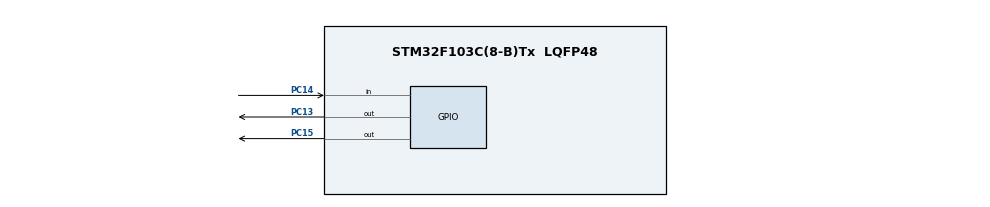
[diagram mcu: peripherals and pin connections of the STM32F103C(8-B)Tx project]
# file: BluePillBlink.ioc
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Mcu.Family=STM32F1
Mcu.Name=STM32F103C(8-B)Tx
Mcu.Package=LQFP48
NVIC.PriorityGroup=NVIC_PRIORITYGROUP_4
PC13-TAMPER-RTC.GPIO_ModeDefaultOutputPP=GPIO_MODE_OUTPUT_PP
PC13-TAMPER-RTC.GPIO_PuPd=GPIO_PULLDOWN
PC13-TAMPER-RTC.GPIO_Speed=GPIO_SPEED_FREQ_HIGH
PC13-TAMPER-RTC.Signal=GPIO_Output
PC14-OSC32_IN.GPIO_PuPd=GPIO_PULLDOWN
PC14-OSC32_IN.Signal=GPIO_Input
PC15-OSC32_OUT.GPIO_PuPd=GPIO_PULLDOWN
PC15-OSC32_OUT.GPIO_Speed=GPIO_SPEED_FREQ_HIGH
PC15-OSC32_OUT.Signal=GPIO_Output
ProjectManager.HeapSize=0x200
ProjectManager.StackSize=0x400
ProjectManager.TargetToolchain=STM32CubeIDE
RCC.APB1Freq_Value=8000000
RCC.APB2Freq_Value=8000000
VP_SYS_VS_ND.Mode=No_Debug
board=custom

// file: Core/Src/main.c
/* USER CODE BEGIN Header */
/**
  ******************************************************************************
  * @file           : main.c
  * @brief          : Main program body
  * @author			: Liyanage Kalana Perera
  *
  ******************************************************************************
  * @attention
  *
  * <h2><center>&copy; Copyright (c) 2023 STMicroelectronics.
  * All rights reserved.</center></h2>
  *
  * This software component is licensed by ST under BSD 3-Clause license,
  * the "License"; You may not use this file except in compliance with the
  * License. You may obtain a copy of the License at:
  *                        opensource.org/licenses/BSD-3-Clause
  *
  *
  * NOTE :
  * --> CONNECTIONS FROM ST-LINK TO STM32 BLUE PILL:
  * 	   SWIO  --> SWDIO
  * 	   SWCLK --> SWCLK
  *
  * --> THERE IS NO "RUN" BUTTON IN THIS VERSION OF IDE. SO TO PROGRAM WE CAN USE "RELESE" BY CLICK ON THE "HAMMER ICON".
  *	--> SET THE BOOT JUMPERS TO
  *		   BOOT0 --> 1
  *		   BOOT1 --> 0
  * --> THE LOGIC IS INVERT FOR THE BUILT IN LED IN C13.
  ******************************************************************************
  */
/* USER CODE END Header */

#include "main.h"

void SystemClock_Config(void);
static void MX_GPIO_Init(void);

/* USER CODE BEGIN 0 */
int PB_STAT,PB_FLAG;
/* USER CODE END 0 */

int main(void)
{

  /* MCU Configuration--------------------------------------------------------*/

  /* Reset of all peripherals, Initializes the Flash interface and the Systick. */
  HAL_Init();

  /* Configure the system clock */
  SystemClock_Config();

  /* Initialize all configured peripherals */
  MX_GPIO_Init();

  /* Infinite loop */
  /* USER CODE BEGIN WHILE */
  while (1)
  {
	  // READ FROM PIN C14 AND STORE IT IN THE "PB_STAT".
	  // CUSTOM DEBOUNCING PART ADDED.
	  PB_STAT = HAL_GPIO_ReadPin(GPIOC, GPIO_PIN_14);
	  // REMEMBER FOR SOME WEIRED RESEON, 1=0 AND 0=1,
	  // FORGET ABOUT THE COMMENT ABOVE. IT'S ONLY VALID FOR THE BUILT IN LED IN C13.
	  // OTHERTHAN THIS, THE LOGIC WORKS FINE.
	  if(PB_STAT == 1 && PB_FLAG == 0)
	   {
		 HAL_Delay(10);
		 PB_FLAG = 1;
	   }
	  if(PB_STAT == 0 && PB_FLAG == 1)
	  	   {
	  		for(int i=0;i<10;i++)
	  		 {
	  		  HAL_GPIO_TogglePin(GPIOC, GPIO_PIN_13);
	  		  HAL_GPIO_TogglePin(GPIOC, GPIO_PIN_15);
	  		  HAL_Delay(50);
	  		 }
	  		PB_FLAG = 0;
	   }else
	   {
		 HAL_GPIO_WritePin(GPIOC, GPIO_PIN_13, GPIO_PIN_RESET);
		 HAL_GPIO_WritePin(GPIOC, GPIO_PIN_15, GPIO_PIN_RESET);
	   }
    /* USER CODE END WHILE */

  }
}

void SystemClock_Config(void)
{
  RCC_OscInitTypeDef RCC_OscInitStruct = {0};
  RCC_ClkInitTypeDef RCC_ClkInitStruct = {0};

  /** Initializes the CPU, AHB and APB busses clocks
  */
  RCC_OscInitStruct.OscillatorType = RCC_OSCILLATORTYPE_HSI;
  RCC_OscInitStruct.HSIState = RCC_HSI_ON;
  RCC_OscInitStruct.HSICalibrationValue = RCC_HSICALIBRATION_DEFAULT;
  RCC_OscInitStruct.PLL.PLLState = RCC_PLL_NONE;
  if (HAL_RCC_OscConfig(&RCC_OscInitStruct) != HAL_OK)
  {
    Error_Handler();
  }
  /** Initializes the CPU, AHB and APB busses clocks
  */
  RCC_ClkInitStruct.ClockType = RCC_CLOCKTYPE_HCLK|RCC_CLOCKTYPE_SYSCLK
                              |RCC_CLOCKTYPE_PCLK1|RCC_CLOCKTYPE_PCLK2;
  RCC_ClkInitStruct.SYSCLKSource = RCC_SYSCLKSOURCE_HSI;
  RCC_ClkInitStruct.AHBCLKDivider = RCC_SYSCLK_DIV1;
  RCC_ClkInitStruct.APB1CLKDivider = RCC_HCLK_DIV1;
  RCC_ClkInitStruct.APB2CLKDivider = RCC_HCLK_DIV1;

  if (HAL_RCC_ClockConfig(&RCC_ClkInitStruct, FLASH_LATENCY_0) != HAL_OK)
  {
    Error_Handler();
  }
}

static void MX_GPIO_Init(void)
{
  GPIO_InitTypeDef GPIO_InitStruct = {0};

  /* GPIO Ports Clock Enable */
  __HAL_RCC_GPIOC_CLK_ENABLE();

  /*Configure GPIO pin Output Level */
  HAL_GPIO_WritePin(GPIOC, GPIO_PIN_13|GPIO_PIN_15, GPIO_PIN_RESET);

  /*Configure GPIO pins : PC13 PC15 */
  GPIO_InitStruct.Pin = GPIO_PIN_13|GPIO_PIN_15;
  GPIO_InitStruct.Mode = GPIO_MODE_OUTPUT_PP;
  GPIO_InitStruct.Pull = GPIO_PULLDOWN;
  GPIO_InitStruct.Speed = GPIO_SPEED_FREQ_HIGH;
  HAL_GPIO_Init(GPIOC, &GPIO_InitStruct);

  /*Configure GPIO pin : PC14 */
  GPIO_InitStruct.Pin = GPIO_PIN_14;
  GPIO_InitStruct.Mode = GPIO_MODE_INPUT;
  GPIO_InitStruct.Pull = GPIO_PULLDOWN;
  HAL_GPIO_Init(GPIOC, &GPIO_InitStruct);

}

void Error_Handler(void)
{
}

/************************ (C) COPYRIGHT STMicroelectronics *****END OF FILE****/
